VERSION ""

NS_ :

BS_:

BU_: New_Node_1

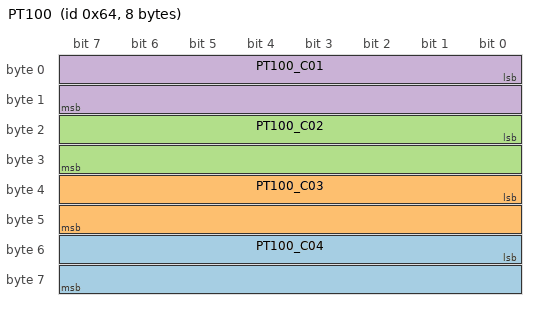
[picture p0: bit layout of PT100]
BO_ 100 PT100: 8 Vector__XXX
 SG_ PT100_C04 : 48|16@1- (0.1,0) [0|0] ""  New_Node_1
 SG_ PT100_C03 : 32|16@1- (0.1,0) [0|0] ""  New_Node_1
 SG_ PT100_C02 : 16|16@1- (0.1,0) [0|0] ""  New_Node_1
 SG_ PT100_C01 : 0|16@1- (0.1,0) [0|0] ""  New_Node_1

BA_DEF_  "BusType" STRING ;
BA_DEF_DEF_  "BusType" "CAN";
